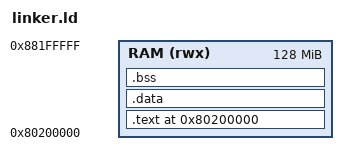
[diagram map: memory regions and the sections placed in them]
OUTPUT_FORMAT("elf64-littleriscv")
OUTPUT_ARCH(riscv)
ENTRY(_start)

MEMORY
{
    RAM (rwx) : ORIGIN = 0x80200000, LENGTH = 128M
}

SECTIONS
{
    . = ORIGIN(RAM);

    .text : {
        KEEP(*(.text.boot))
        *(.text .text.*)
        *(.rodata .rodata.*)
    } > RAM

    .data : {
        *(.data .data.*)
    } > RAM

    .bss : {
        __bss_start = .;
        *(.bss .bss.*)
        *(COMMON)
        __bss_end = .;
    } > RAM

    /DISCARD/ : {
        *(.comment)
        *(.note*)
    }
}
